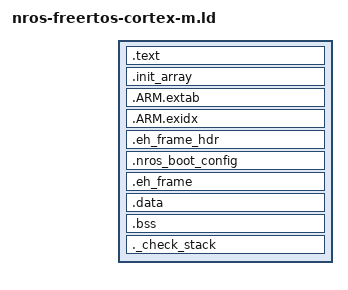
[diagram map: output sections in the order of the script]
/*
 * Shared Cortex-M + FreeRTOS section layout for nano-ros boards.
 *
 * phase-337 W5.e — this was a 135-line per-board file whose only board content
 * was the MEMORY block (2 lines) and `_estack`. The board now supplies those
 * three numbers and pulls this in:
 *
 *     MEMORY { FLASH (rx)  : ORIGIN = …, LENGTH = …
 *              RAM   (rwx) : ORIGIN = …, LENGTH = … }
 *     _estack = ORIGIN(RAM) + LENGTH(RAM);
 *     INCLUDE nros-freertos-cortex-m.ld
 *
 * `INCLUDE` resolves against the linker's -L search path, so BOTH lanes put
 * this directory on it: the cargo lane's board `build.rs` copies both scripts
 * into OUT_DIR (already a `rustc-link-search`), the CMake lane's board overlay
 * appends `-L<this dir>` to `freertos_platform`'s link options.
 *
 * Requires from the board: MEMORY regions FLASH and RAM, and `_estack`.
 *
 * FreeRTOS heap is managed by heap_4.c using ucHeap[] (configTOTAL_HEAP_SIZE),
 * which lands in .bss below.
 */

/* Minimum main stack size (used before FreeRTOS scheduler starts) */
_Min_Stack_Size = 0x2000;  /* 8 KB */

ENTRY(Reset_Handler)

SECTIONS
{
    /* Vector table + code */
    .text :
    {
        . = ALIGN(4);
        KEEP(*(.isr_vector))
        *(.text)
        *(.text*)
        *(.rodata)
        *(.rodata*)
        . = ALIGN(4);
    } > FLASH

    /* Static-constructor table (phase-370 W4, the #195 pattern).
     *
     * The Cyclone message descriptors register from
     * `__attribute__((constructor))` TUs (`register_std_msgs_*`, generated by
     * `nros_rmw_cyclonedds_idlc_compile`). This is a flat bare-metal image with
     * no crt0 / `__libc_init_array`, so nothing walks `.init_array` unless the
     * board does it explicitly — `nros_board_freertos_run_init_array()` in
     * `c/freertos_hooks.c` does, and the walk needs these bounds.
     *
     * Without the section the ctors are ORPHANED: the descriptor objects are in
     * the image (the type-support archives are whole-archived precisely to keep
     * them — see NrosRmwCycloneddsTypeSupport.cmake), but the ctor bodies have
     * no output section, so they are discarded and never run. The registry then
     * stays empty and every writer/reader create fails, which presented as a
     * bare `nros_publisher_init(...) -> -1` naming nothing (issue 0733).
     *
     * `KEEP` because `--gc-sections` is on: nothing REFERENCES a ctor, so
     * without it the entries go even once the section exists — the same trap
     * `link.lds` records for threadx-riscv64.
     *
     * FLASH, read-only: these are function pointers, not state. */
    .init_array :
    {
        . = ALIGN(4);
        PROVIDE(__init_array_start = .);
        KEEP(*(SORT_BY_INIT_PRIORITY(.init_array.*)))
        KEEP(*(.init_array))
        PROVIDE(__init_array_end = .);
        . = ALIGN(4);
    } > FLASH

    /* ARM exception unwinding tables (.ARM.extab) — referenced by
     * .ARM.exidx, placed before it in FLASH. Phase 97.1.linker:
     * DDS emits extab entries for its panic unwind paths;
     * without explicit placement they fall to the default
     * read-only output and overlap .data on bare-metal Cortex-M.
     */
    .ARM.extab :
    {
        *(.ARM.extab* .gnu.linkonce.armextab.*)
        . = ALIGN(4);
    } > FLASH

    /* ARM exception unwinding (placed in FLASH after .text) */
    .ARM.exidx :
    {
        __exidx_start = .;
        *(.ARM.exidx*)
        __exidx_end = .;
        . = ALIGN(4);
    } > FLASH

    /* DWARF CFI (.eh_frame / .eh_frame_hdr) — newer rustc/rust-lld emit these
     * (and lld synthesizes .eh_frame_hdr under --eh-frame-hdr) for the same DDS
     * panic-unwind paths as .ARM.extab. ARM bare-metal unwinds via exidx/extab,
     * so eh_frame is unused at runtime, but it MUST get a FLASH load address —
     * left unplaced it falls to the default output and overlaps .data/RAM
     * (`rust-lld: section .eh_frame_hdr load address range overlaps with .data`).
     */
    .eh_frame_hdr :
    {
        *(.eh_frame_hdr)
        . = ALIGN(4);
    } > FLASH

    /* Baked boot config (phase-266 / RFC-0045, issue #108) — `nros::main!()`
     * emits the node name + deploy overlay into `.nros_boot_config` via
     * `#[link_section]`. Read-only; MUST get a FLASH load address or it falls to
     * the default output and overlaps .data/RAM — exactly the class fixed above
     * for .eh_frame_hdr (`section .nros_boot_config load address range overlaps
     * with .data`). cortex-m-rt's link.x absorbs it for the bare-metal/RTIC
     * entries; this hand FreeRTOS script must place it explicitly. */
    .nros_boot_config :
    {
        KEEP(*(.nros_boot_config))
        KEEP(*(.nros_boot_config*))
        . = ALIGN(4);
    } > FLASH

    .eh_frame :
    {
        *(.eh_frame)
        . = ALIGN(4);
        _etext = .;
    } > FLASH

    /* Initialized data — loaded from flash, copied to RAM at startup */
    .data : AT(_etext)
    {
        . = ALIGN(4);
        _sdata = .;
        *(.data)
        *(.data*)
        . = ALIGN(8);
        __tls_base = .;
        *(.tdata)
        *(.tdata*)
        *(.tbss)
        *(.tbss*)
        . = ALIGN(4);
        _edata = .;
    } > RAM

    /* Zero-initialized data.
     *
     * phase-372 root-cause (the "image boots or hardfaults depending on
     * unrelated rebuilds" flicker): without NOLOAD + an explicit AT>RAM,
     * .bss CONTINUES .data's load region — one PT_LOAD whose LMA sits at
     * _etext in FLASH and whose p_memsz includes the multi-MiB heap that
     * lives here. QEMU's ROM loader registers that blob as
     * [_etext, _etext + memsz), and whenever _etext drifts high enough for
     * the span to cross the code region's end, load_elf rejects the WHOLE
     * image SILENTLY: the machine then executes zeroed memory and dies in
     * a lockup that looks like a code bug. Whether any given build trips
     * it is a function of text-size drift — which is why byte-equivalent
     * rebuilds flickered between booting and faulting for days. AT>RAM
     * pins the segment's paddr to its vaddr (inside the RAM region, where
     * it always fits) and NOLOAD keeps the multi-MiB span out of the
     * file. */
    .bss (NOLOAD) : AT(ADDR(.bss))
    {
        . = ALIGN(4);
        _sbss = .;
        __bss_start__ = _sbss;
        *(.bss)
        *(.bss*)
        *(COMMON)
        . = ALIGN(4);
        _ebss = .;
        __bss_end__ = _ebss;
        end = .;           /* newlib _sbrk heap start */
        __end__ = .;
    } > RAM

    /* Ensure enough room for the main stack */
    ._check_stack (NOLOAD) :
    {
        . = ALIGN(4);
        . = . + _Min_Stack_Size;
        . = ALIGN(4);
    } > RAM
}
